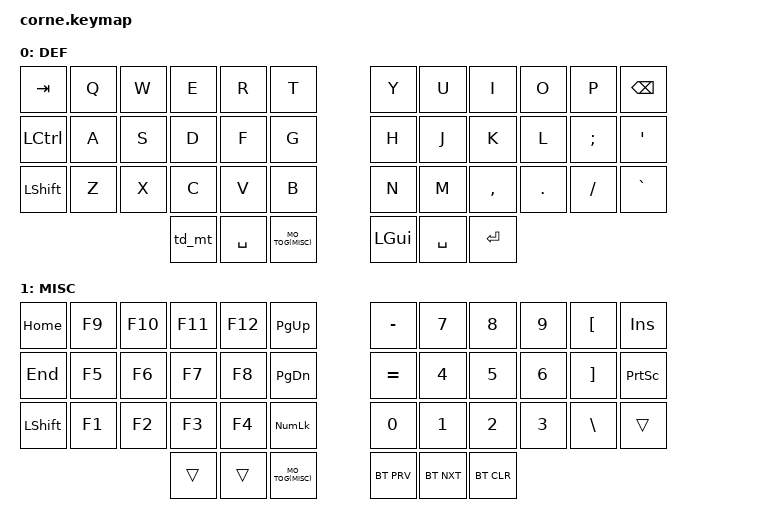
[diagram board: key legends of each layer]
#include <behaviors.dtsi>
#include <dt-bindings/zmk/keys.h>
#include <dt-bindings/zmk/bt.h>

#define DEFAULT 0
#define MISC 1

#define MO_TOG(layer) &mo_tog layer layer // Apply momentary-layer-on-hold/toggle-layer-on-tap to specific layer

/ {
        behaviors {
            mo_tog: behavior_mo_tog {
                compatible = "zmk,behavior-hold-tap";
                label = "MO_TOG";
                #binding-cells = <2>;
                tapping-term-ms = <200>;
                flavor = "hold-preferred";
                bindings = <&mo>, <&tog>;
            };

            td_mt: tap_dance_mod_tap {
                compatible = "zmk,behavior-tap-dance";
                label = "TAP_DANCE_MOD_TAP";
                #binding-cells = <0>;
                tapping-term-ms = <200>;
                bindings = <&mt LALT ESC>, <&kp CAPSLOCK>;
            };
        };
    
        keymap {
                compatible = "zmk,keymap";

                default_layer {
// -----------------------------------------------------------------------------------------
// | TAB  | Q | W |  E  |  R  |  T   |   |  Y   |   U  |  I  |  O  |  P  | BKSP |
// | CTRL | A | S |  D  |  F  |  G   |   |  H   |   J  |  K  |  L  |  ;  |  '   |
// | SHFT | Z | X |  C  |  V  |  B   |   |  N   |   M  |  ,  |  .  |  /  |  `   |
//                | ALT | SPC | MISC |   | LGUI |  SPC | ENT |
                        label = "DEF";
                        bindings = <
   &kp TAB   &kp Q &kp W &kp E  &kp R     &kp T           &kp Y    &kp U     &kp I     &kp O   &kp P    &kp BSPC
   &kp LCTRL &kp A &kp S &kp D  &kp F     &kp G           &kp H    &kp J     &kp K     &kp L   &kp SEMI &kp SQT
   &kp LSHFT &kp Z &kp X &kp C  &kp V     &kp B           &kp N    &kp M     &kp COMMA &kp DOT &kp FSLH &kp GRAVE
                         &td_mt &kp SPACE MO_TOG(MISC)    &kp LGUI &kp SPACE &kp RET
                        >;
                };

                misc {
// -----------------------------------------------------------------------------------------
// | HOME | F9 | F10 | F11 | F12 | PGUP  |   |    -   |    7   |    8   | 9 | [ |  INS  |
// | END  | F5 |  F6 | F7  | F8  | PGDN  |   |    =   |    4   |    5   | 6 | ] | PSCRN |
// | SHFT | F1 |  F2 | F3  | F4  | NUMLK |   |    0   |    1   |    2   | 3 | \ |       |
//                   |     |     |  DEF  |   | BT_PRV | BT_NXT | BT_CLR |
                        label = "MISC";
                        bindings = <
   &kp HOME  &kp F9  &kp F10 &kp F11 &kp F12 &kp PG_UP       &kp MINUS  &kp N7     &kp N8 &kp N9 &kp LBKT &kp INS
   &kp END   &kp F5  &kp F6  &kp F7  &kp F8  &kp PG_DN       &kp EQUAL  &kp N4     &kp N5 &kp N6 &kp RBKT &kp PSCRN
   &kp LSHFT &kp F1  &kp F2  &kp F3  &kp F4  &kp KP_NUM      &kp N0     &kp N1     &kp N2 &kp N3 &kp BSLH &trans
                             &trans  &trans  MO_TOG(MISC)    &bt BT_PRV &bt BT_NXT &bt BT_CLR
                        >;
                };
        };
};
